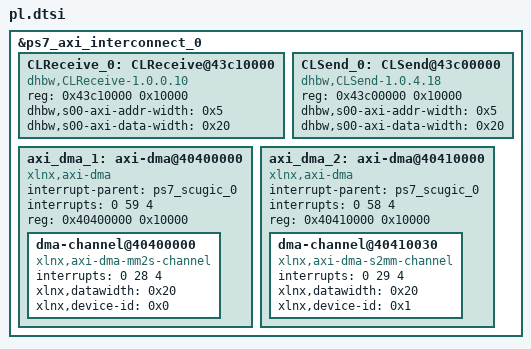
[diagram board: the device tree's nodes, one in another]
/*
 * CAUTION: This file is automatically generated by Xilinx.
 * Version:  
 * Today is: Wed Aug 13 12:53:54 2014
*/

	&ps7_axi_interconnect_0 {
		ranges;
		CLReceive_0: CLReceive@43c10000 {
			compatible = "dhbw,CLReceive-1.0.0.10";
			reg = <0x43c10000 0x10000>;
			dhbw,s00-axi-addr-width = <0x5>;
			dhbw,s00-axi-data-width = <0x20>;
		} ;
		CLSend_0: CLSend@43c00000 {
			compatible = "dhbw,CLSend-1.0.4.18";
			reg = <0x43c00000 0x10000>;
			dhbw,s00-axi-addr-width = <0x5>;
			dhbw,s00-axi-data-width = <0x20>;
		} ;
		axi_dma_1: axi-dma@40400000 {
			compatible = "xlnx,axi-dma";
			interrupt-parent = <&ps7_scugic_0>;
			interrupts = <0 59 4>;
			reg = <0x40400000 0x10000>;
			dma-channel@40400000 {
				compatible = "xlnx,axi-dma-mm2s-channel";
				interrupts = <0 28 4>;
				xlnx,datawidth = <0x20>;
				xlnx,device-id = <0x0>;
			} ;
		} ;
		axi_dma_2: axi-dma@40410000 {
			compatible = "xlnx,axi-dma";
			interrupt-parent = <&ps7_scugic_0>;
			interrupts = <0 58 4>;
			reg = <0x40410000 0x10000>;
			dma-channel@40410030 {
				compatible = "xlnx,axi-dma-s2mm-channel";
				interrupts = <0 29 4>;
				xlnx,datawidth = <0x20>;
				xlnx,device-id = <0x1>;
			} ;
		} ;
	} ;
